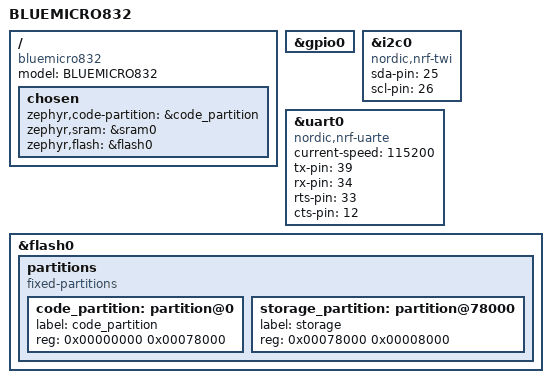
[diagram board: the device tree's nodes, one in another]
/*
 * Copyright (c) 2020 Pete Johanson, Derek Schmell
 *
 * SPDX-License-Identifier: MIT
 */

/dts-v1/;
#include <nordic/nrf52832_qfaa.dtsi>
#include "arduino_pro_micro_pins.dtsi"

/ {
	model = "BLUEMICRO832";
	compatible = "bluemicro832";

	chosen {
		zephyr,code-partition = &code_partition;
		// zephyr,console = &uart0;
		//zephyr,bt-mon-uart = &uart0;
		//zephyr,bt-c2h-uart = &uart0;
		zephyr,sram = &sram0;
		zephyr,flash = &flash0;
	};

};

&gpio0 {
	status = "okay";
};


&i2c0 {
	compatible = "nordic,nrf-twi";
	sda-pin = <25>;
	scl-pin = <26>;
};

&uart0 {
	compatible = "nordic,nrf-uarte";
	status = "okay";
	current-speed = <115200>;
	tx-pin = <39>;
	rx-pin = <34>;
	rts-pin = <33>;
	cts-pin = <12>;
};



&flash0 {
	/*
	 * For more information, see:
	 * http://docs.zephyrproject.org/latest/devices/dts/flash_partitions.html
	 */
	partitions {
		compatible = "fixed-partitions";
		#address-cells = <1>;
		#size-cells = <1>;
		code_partition: partition@0 {
			label = "code_partition";
			reg = <0x00000000 0x00078000>;
		};

		storage_partition: partition@78000 {
			label = "storage";
			reg = <0x00078000 0x00008000>;
		};

	};
};

